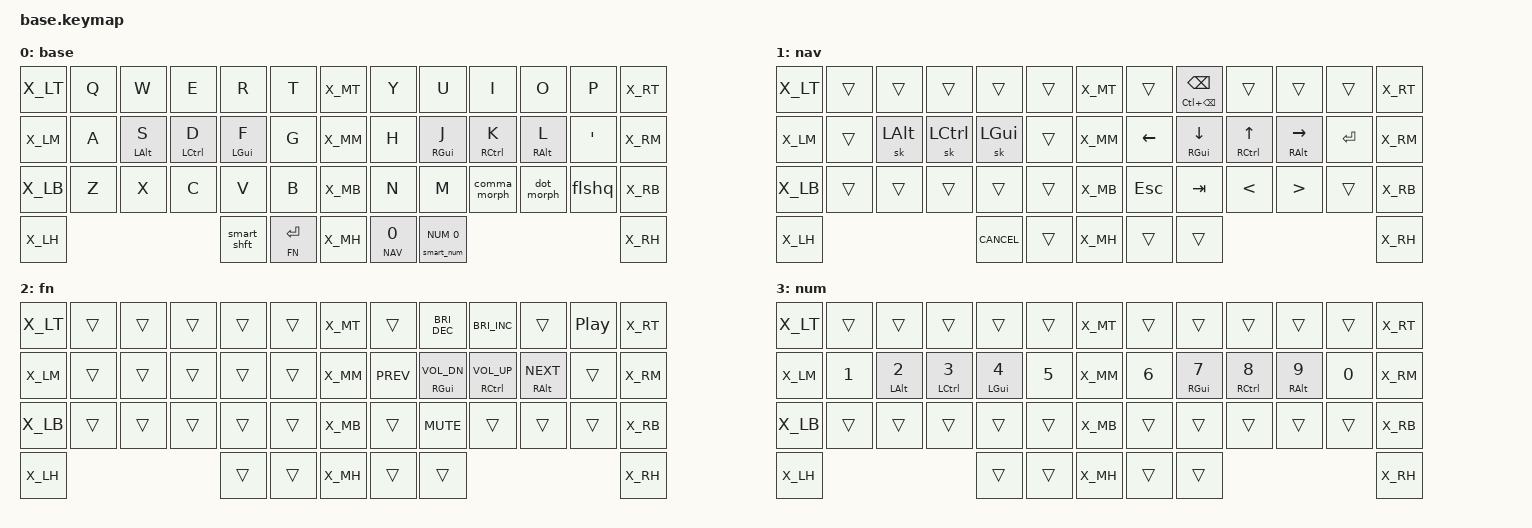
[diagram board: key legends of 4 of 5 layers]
#include <behaviors.dtsi>
#include <dt-bindings/zmk/keys.h>
#if CONFIG_WIRELESS
    #include <dt-bindings/zmk/bt.h>
    #define _BT_SEL_KEYS_ &bt BT_SEL 0 &trans &trans &bt BT_SEL 3 &bt BT_CLR
#else
    #define _BT_SEL_KEYS_ &trans &trans &trans &trans &trans
#endif

#include "../zmk-nodefree-config/helper.h"

#define DEF 0
#define NAV 1
#define FN 2
#define NUM 3
#define SYS 4
#define MOUSE 5

#include "combos.dtsi"  // requires layer aliases
#include "extra_keys.h"

#define XXX &none
#define ___ &trans

/* Global settings */

#define QUICK_TAP_MS 175

&sk {  // sticky-key config
    release-after-ms = <900>;  // release after 0.6s
    quick-release;             // no double capitalization when rolling keys
};

&sl {  // sticky-layer config
    ignore-modifiers;          // allow chording sticky mods & layers
};

&lt {  // layer-tap config
    flavor = "balanced";
    tapping-term-ms = <200>;
    quick-tap-ms = <QUICK_TAP_MS>;
};

/* Homerow mods */

#define KEYS_L LT0 LT1 LT2 LT3 LT4 LM0 LM1 LM2 LM3 LM4 LB0 LB1 LB2 LB3 LB4  // left hand
#define KEYS_R RT0 RT1 RT2 RT3 RT4 RM0 RM1 RM2 RM3 RM4 RB0 RB1 RB2 RB3 RB4  // right hand
#define THUMBS LH1 LH0 RH0 RH1                                              // thumbs

#define MAKE_HRM(NAME, HOLD, TAP, TRIGGER_POS) \
    ZMK_BEHAVIOR(NAME, hold_tap, \
        flavor = "balanced"; \
        tapping-term-ms = <280>; \
        quick-tap-ms = <QUICK_TAP_MS>; \
        require-prior-idle-ms = <150>; \
        bindings = <HOLD>, <TAP>; \
        hold-trigger-key-positions = <TRIGGER_POS>; \
        hold-trigger-on-release; \
    )
MAKE_HRM(hml, &kp, &kp, KEYS_R THUMBS)  // left-hand HRMs
MAKE_HRM(hmr, &kp, &kp, KEYS_L THUMBS)  // right-hand HRMs

MAKE_HRM(hml_repeat, &kp, &key_repeat, KEYS_R THUMBS)  // used for HRM-combo
MAKE_HRM(hmr_lpar_lt, &kp, &lpar_lt, KEYS_L THUMBS)    // "    "   "   "
MAKE_HRM(hmr_rpar_gt, &kp, &rpar_gt, KEYS_L THUMBS)    // "    "   "   "

/* Nav cluster */

// long-tap action on hold, short-tap action on all interrupts
#define MT_CORE \
    flavor = "tap-preferred"; \
    tapping-term-ms = <220>; \
    quick-tap-ms = <220>; \
    hold-trigger-key-positions = <0>;

&mt { MT_CORE };
ZMK_BEHAVIOR(mt_home, hold_tap, bindings = <&masked_home>, <&kp>; MT_CORE)
ZMK_BEHAVIOR(mt_end,  hold_tap,  bindings = <&masked_end>, <&kp>; MT_CORE)

#define NAV_LEFT  &kp LEFT
#define NAV_RIGHT &hmr RALT RIGHT
#define NAV_UP    &hmr RCTRL UP
#define NAV_DOWN  &hmr RGUI  DOWN
#define NAV_BSPC  &mt LC(BSPC) BSPC    // tap: bspc  | long-tap: delete word backward
#define NAV_DEL   &mt LC(DEL)  DEL     // tap: del   | long-tap: delete word forward

// mask CTRL when holding left/right to avoid accidental jumps to beginning/end of document
#define MASK_MODS(NAME, MODS, BINDING) \
    ZMK_BEHAVIOR(NAME, mod_morph, \
        bindings = <BINDING>, <BINDING>; \
        mods = <MODS>; \
    )
MASK_MODS(masked_home, (MOD_LCTL), &kp HOME)
MASK_MODS(masked_end,  (MOD_LCTL), &kp END)

/* Caps-word, num-word and smart-mouse */

// tap: sticky-shift | shift + tap/ double-tap: caps-word | hold: shift
ZMK_BEHAVIOR(smart_shft, mod_morph,
    bindings = <&sk LSHFT>, <&caps_word>;
    mods = <(MOD_LSFT)>;
)
&caps_word {  // mods deactivate caps-word, requires PR #1451
    /delete-property/ ignore-modifiers;
};

// tap: num-word | double-tap: sticky num-layer | hold: num-layer
#define SMART_NUM &smart_num NUM 0
ZMK_BEHAVIOR(smart_num, hold_tap,
    flavor = "balanced";
    tapping-term-ms = <200>;
    quick-tap-ms = <QUICK_TAP_MS>;
    bindings = <&mo>, <&num_dance>;
)
ZMK_BEHAVIOR(num_dance, tap_dance,
    tapping-term-ms = <200>;
    bindings = <&num_word>, <&sl NUM>;  // reverse this for sticky-num on single tap
)
&num_word {  // num-word, requires PR #1451
    layers = <NUM>;
    continue-list = <BSPC DEL DOT COMMA PLUS MINUS STAR FSLH EQUAL>;
};


/* Custom behaviors */

// Alt+Tab swapper, requires PR #1366
ZMK_BEHAVIOR(swapper, tri_state,
    bindings = <&kt LALT>, <&kp TAB>, <&kt LALT>;
    ignored-key-positions = <LT2>;
)

// Sticky layer + sticky shift (workaround for issue #1421)
/*ZMK_BEHAVIOR(sls, sticky_key,
    release-after-ms = <1000>;
    bindings = <&uc_shift>;
    ignore-modifiers;
)
ZMK_BEHAVIOR(uc_shift, macro,
    wait-ms = <0>;
    tap-ms = <1>;
    bindings = <&macro_press &mo UC &kp LSHFT>
             , <&macro_pause_for_release>
             , <&macro_release &mo UC &kp LSHFT>;
)*/

// reuse basic mod-morph scheme
#define SIMPLE_MORPH(NAME, MOD, BINDING1, BINDING2) \
    ZMK_BEHAVIOR(NAME, mod_morph, \
        mods = <(MOD_L ## MOD|MOD_R ## MOD)>; \
        bindings = <BINDING1>, <BINDING2>; \
    )

// tap: comma | shift + tap: semicolon | ctrl + shift + tap: <
SIMPLE_MORPH(comma_morph, SFT, &kp COMMA, &comma_inner_morph)
SIMPLE_MORPH(comma_inner_morph, CTL, &kp SEMICOLON, &kp LESS_THAN)

// tap: dot | shift + tap: colon | ctrl + shift + tap: >
SIMPLE_MORPH(dot_morph, SFT, &kp DOT, &dot_inner_morph)
SIMPLE_MORPH(dot_inner_morph, CTL, &kp COLON, &kp GREATER_THAN)

// tap: qmark | shift + tap: excl
SIMPLE_MORPH(qexcl, SFT, &kp QMARK, &kp EXCL)

// tap: left/right parenthesis | shft + tap: less-than/greater-than
SIMPLE_MORPH(lpar_lt, SFT, &kp LPAR, &kp LT)
SIMPLE_MORPH(rpar_gt, SFT, &kp RPAR, &kp GT)

// tap: fslh | shift + tap: qmark
SIMPLE_MORPH(flshq, SFT, &kp FSLH, &kp QMARK)

// tap: space | shift + tap: dot -> space -> sticky shift | hold: activate layer
ZMK_BEHAVIOR(lt_spc, hold_tap,
    flavor = "balanced";
    tapping-term-ms = <200>;
    quick-tap-ms = <QUICK_TAP_MS>;
    bindings = <&mo>, <&spc_morph>;
)
SIMPLE_MORPH(spc_morph, SFT, &kp SPACE, &dot_spc)
ZMK_BEHAVIOR(dot_spc, macro,
    wait-ms = <0>;
    tap-ms = <5>;
    bindings = <&kp DOT &kp SPACE &sk LSHFT>;
)

// tap: backspace | lshft + tap: delete | rshft + tap: shift-delete
ZMK_BEHAVIOR(bs_del, mod_morph,
    bindings = <&kp BSPC>, <&kp DEL>;
    mods = <(MOD_LSFT|MOD_RSFT)>;
    keep-mods = <MOD_RSFT>;
)

// tap: copy | double-tap: cut
ZMK_BEHAVIOR(copy_cut, tap_dance,
    tapping-term-ms = <200>;
    bindings = <&kp LC(INS)>, <&kp LC(X)>;
)

// Windows sleep key
ZMK_BEHAVIOR(win_sleep, macro,
    wait-ms = <500>;
    tap-ms = <50>;
    bindings = <&kp LG(X) &kp U &kp S>;
)

// misc aliases
#define CANCEL      &kp K_CANCEL             // cancel caps-word, num-word and smart-mouse
#define VOL_DOWN    &hmr RGUI C_VOL_DN
#define VOL_UP      &hmr RCTRL C_VOL_UP
#define NEXT_TRK    &hmr RALT C_NEXT

/* Keymap */

ZMK_CONDITIONAL_LAYER(FN NUM, SYS)  // FN + NUM --> SYS

ZMK_LAYER(base,
//╭──────╮ ╭─────────────┬─────────────┬─────────────┬─────────────┬─────────────╮ ╭──────╮ ╭─────────────┬─────────────┬─────────────┬─────────────┬─────────────╮ ╭──────╮
    X_LT     &kp Q         &kp W         &kp E         &kp R         &kp T           X_MT     &kp Y         &kp U         &kp I         &kp O         &kp P           X_RT
//├──────┤ ├─────────────┼─────────────┼─────────────┼─────────────┼─────────────┤ ├──────┤ ├─────────────┼─────────────┼─────────────┼─────────────┼─────────────┤ ├──────┤
    X_LM     &kp A         &hml LALT S   &hml LCTRL D  &hml LGUI F   &kp G           X_MM     &kp H         &hmr RGUI J   &hmr RCTRL K  &hmr RALT L   &kp SQT         X_RM
//├──────┤ ├─────────────┼─────────────┼─────────────┼─────────────┼─────────────┤ ├──────┤ ├─────────────┼─────────────┼─────────────┼─────────────┼─────────────┤ ├──────┤
    X_LB     &kp Z         &kp X         &kp C         &kp V         &kp B           X_MB     &kp N         &kp M         &comma_morph  &dot_morph    &flshq          X_RB
//├──────┤ ╰─────────────┼─────────────┴─────────────┼─────────────┼─────────────┤ ├──────┤ ├─────────────┼─────────────┼─────────────┴───────────────────────────╯ ├──────┤
    X_LH                                               &smart_shft   &lt FN RET      X_MH     &lt_spc NAV 0 SMART_NUM                                                 X_RH
//╰──────╯                                           ╰─────────────┴─────────────╯ ╰──────╯ ╰─────────────┴─────────────╯                                           ╰──────╯
)

ZMK_LAYER(nav,
//╭──────╮ ╭─────────────┬─────────────┬─────────────┬─────────────┬─────────────╮ ╭──────╮ ╭─────────────┬─────────────┬─────────────┬─────────────┬─────────────╮ ╭──────╮
    X_LT     ___           ___           ___           ___           ___             X_MT     ___           NAV_BSPC      ___           ___           ___             X_RT
//├──────┤ ├─────────────┼─────────────┼─────────────┼─────────────┼─────────────┤ ├──────┤ ├─────────────┼─────────────┼─────────────┼─────────────┼─────────────┤ ├──────┤
    X_LM     ___           &sk LALT      &sk LCTRL     &sk LGUI      ___             X_MM     NAV_LEFT      NAV_DOWN      NAV_UP        NAV_RIGHT     &kp RET         X_RM
//├──────┤ ├─────────────┼─────────────┼─────────────┼─────────────┼─────────────┤ ├──────┤ ├─────────────┼─────────────┼─────────────┼─────────────┼─────────────┤ ├──────┤
    X_LB     ___           ___           ___           ___           ___             X_MB     &kp ESC       &kp TAB       &kp LT        &kp GT        ___             X_RB
//├──────┤ ╰─────────────┼─────────────┴─────────────┼─────────────┼─────────────┤ ├──────┤ ├─────────────┼─────────────┼─────────────┴───────────────────────────╯ ├──────┤
    X_LH                                               CANCEL        ___             X_MH     ___           ___                                                       X_RH
//╰──────╯                                           ╰─────────────┴─────────────╯ ╰──────╯ ╰─────────────┴─────────────╯                                           ╰──────╯
)

ZMK_LAYER(fn,
//╭──────╮ ╭─────────────┬─────────────┬─────────────┬─────────────┬─────────────╮ ╭──────╮ ╭─────────────┬─────────────┬─────────────┬─────────────┬─────────────╮ ╭──────╮
    X_LT     ___           ___           ___           ___           ___             X_MT     ___          &kp C_BRI_DEC &kp C_BRI_INC  ___           &kp C_PP        X_RT
//├──────┤ ├─────────────┼─────────────┼─────────────┼─────────────┼─────────────┤ ├──────┤ ├─────────────┼─────────────┼─────────────┼─────────────┼─────────────┤ ├──────┤
    X_LM     ___           ___           ___           ___           ___             X_MM     &kp C_PREV    VOL_DOWN      VOL_UP        NEXT_TRK      ___             X_RM
//├──────┤ ├─────────────┼─────────────┼─────────────┼─────────────┼─────────────┤ ├──────┤ ├─────────────┼─────────────┼─────────────┼─────────────┼─────────────┤ ├──────┤
    X_LB     ___           ___           ___           ___           ___             X_MB     ___           &kp C_MUTE    ___           ___           ___             X_RB
//├──────┤ ╰─────────────┼─────────────┴─────────────┼─────────────┼─────────────┤ ├──────┤ ├─────────────┼─────────────┼─────────────┴───────────────────────────╯ ├──────┤
    X_LH                                               ___           ___             X_MH     ___           ___                                                       X_RH
//╰──────╯                                           ╰─────────────┴─────────────╯ ╰──────╯ ╰─────────────┴─────────────╯                                           ╰──────╯
)

ZMK_LAYER(num,
//╭──────╮ ╭─────────────┬─────────────┬─────────────┬─────────────┬─────────────╮ ╭──────╮ ╭─────────────┬─────────────┬─────────────┬─────────────┬─────────────╮ ╭──────╮
    X_LT     ___           ___           ___           ___           ___             X_MT     ___           ___           ___           ___           ___             X_RT
//├──────┤ ├─────────────┼─────────────┼─────────────┼─────────────┼─────────────┤ ├──────┤ ├─────────────┼─────────────┼─────────────┼─────────────┼─────────────┤ ├──────┤
    X_LM     &kp N1        &hml LALT N2  &hml LCTRL N3 &hml LGUI N4  &kp N5          X_MM     &kp N6        &hmr RGUI N7  &hmr RCTRL N8 &hmr RALT N9  &kp N0          X_RM
//├──────┤ ├─────────────┼─────────────┼─────────────┼─────────────┼─────────────┤ ├──────┤ ├─────────────┼─────────────┼─────────────┼─────────────┼─────────────┤ ├──────┤
    X_LB     ___           ___           ___           ___           ___             X_MB     ___           ___           ___           ___           ___             X_RB
//├──────┤ ╰─────────────┼─────────────┴─────────────┼─────────────┼─────────────┤ ├──────┤ ├─────────────┼─────────────┼─────────────┴───────────────────────────╯ ├──────┤
    X_LH                                               ___           ___             X_MH     ___           ___                                                       X_RH
//╰──────╯                                           ╰─────────────┴─────────────╯ ╰──────╯ ╰─────────────┴─────────────╯                                           ╰──────╯
)

ZMK_LAYER(sys,
//╭──────╮ ╭─────────────┬─────────────┬─────────────┬─────────────┬─────────────╮ ╭──────╮ ╭─────────────┬─────────────┬─────────────┬─────────────┬─────────────╮ ╭──────╮
    X_LT                           _BT_SEL_KEYS_                                     X_MT     ___           ___           ___           ___           ___             X_RT
//├──────┤ ├─────────────┼─────────────┼─────────────┼─────────────┼─────────────┤ ├──────┤ ├─────────────┼─────────────┼─────────────┼─────────────┼─────────────┤ ├──────┤
    X_LM     ___           ___           ___           ___           ___             X_MM     ___           ___           ___           ___           ___             X_RM
//├──────┤ ├─────────────┼─────────────┼─────────────┼─────────────┼─────────────┤ ├──────┤ ├─────────────┼─────────────┼─────────────┼─────────────┼─────────────┤ ├──────┤
    X_LB     ___           ___           ___           ___           ___             X_MB     ___           ___           ___           ___           ___             X_RB
//├──────┤ ╰─────────────┼─────────────┴─────────────┼─────────────┼─────────────┤ ├──────┤ ├─────────────┼─────────────┼─────────────┴───────────────────────────╯ ├──────┤
    X_LH                                               ___           ___             X_MH     ___           ___                                                       X_RH
//╰──────╯                                           ╰─────────────┴─────────────╯ ╰──────╯ ╰─────────────┴─────────────╯                                           ╰──────╯
)

/* vim: set ft=c tw=174: */
